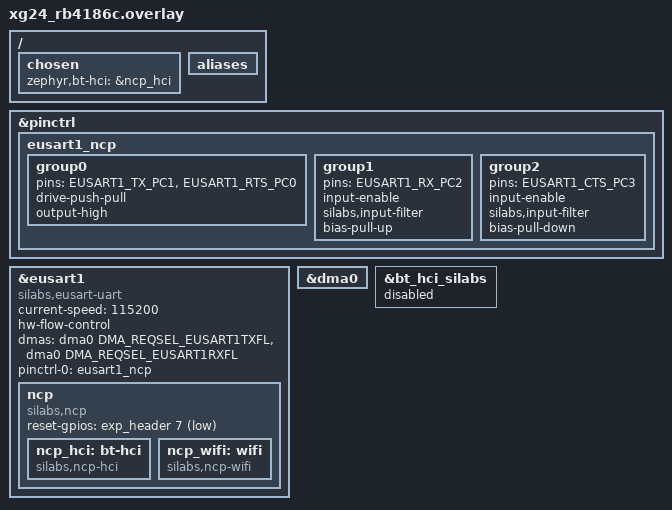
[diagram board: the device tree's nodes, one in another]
/*
 * Copyright (c) 2026 Silicon Laboratories Inc.
 * SPDX-License-Identifier: Apache-2.0
 */

/ {
	chosen {
		zephyr,bt-hci = &ncp_hci;
		/* The memory LCD and the SPI flash sit on the EUSART given to the
		 * co-processor.
		 */
		/delete-property/ zephyr,display;
	};

	aliases {
		/delete-property/ spi-flash0;
	};
};

&pinctrl {
	eusart1_ncp: eusart1_ncp {
		group0 {
			pins = <EUSART1_TX_PC1>,  /* EXP 4 - P1 */
			       <EUSART1_RTS_PC0>; /* EXP 10 - P7 */
			drive-push-pull;
			output-high;
		};

		group1 {
			pins = <EUSART1_RX_PC2>; /* EXP 6 - P3 */
			input-enable;
			silabs,input-filter;
			/* Keep RX idle high when nothing is connected */
			bias-pull-up;
		};

		group2 {
			pins = <EUSART1_CTS_PC3>; /* EXP 8 - P5 */
			input-enable;
			silabs,input-filter;
			/* Allow transmission when the co-processor does not drive RTS */
			bias-pull-down;
		};
	};
};

&eusart1 {
	compatible = "silabs,eusart-uart";
	/delete-property/ clock-frequency;
	/delete-property/ cs-gpios;
	/delete-property/ #address-cells;
	/delete-property/ #size-cells;
	/delete-node/ ls0xx@0;
	/delete-node/ mx25r8035f@1;
	current-speed = <115200>;
	hw-flow-control;
	dmas = <&dma0 DMA_REQSEL_EUSART1TXFL>,
	       <&dma0 DMA_REQSEL_EUSART1RXFL>;
	dma-names = "tx", "rx";
	pinctrl-0 = <&eusart1_ncp>;
	pinctrl-names = "default";
	status = "okay";

	ncp: ncp {
		compatible = "silabs,ncp";
		reset-gpios = <&exp_header 7 GPIO_ACTIVE_LOW>; /* EXP 7 - P4 - PA5 */

		ncp_hci: bt-hci {
			compatible = "silabs,ncp-hci";
		};

		ncp_wifi: wifi {
			compatible = "silabs,ncp-wifi";
		};
	};
};

&dma0 {
	status = "okay";
};

/* The Bluetooth controller is the one of the co-processor */
&bt_hci_silabs {
	status = "disabled";
};
